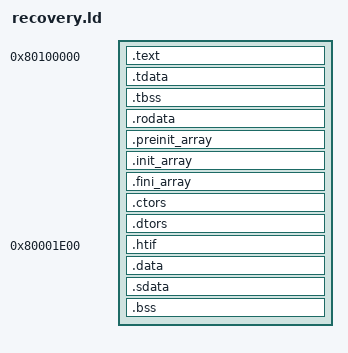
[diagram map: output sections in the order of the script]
/* Linker script for the recovery firmware image.
 * Identical to chipyard's htif.ld except linked at 0x80100000 instead of
 * 0x80000000. The BootROM mret's here when verification fails, emulating
 * production secure-boot recovery firmware loaded into a separate region. */
OUTPUT_ARCH ("riscv")
ENTRY (_start)

SECTIONS
{
    . = 0x80100000;

    /* Keep under a power of 2 to reserve space for TCB */
    PROVIDE (__stack_size_min = 24K);

    .text : {
        *(.text.init)
        *(.text.unlikely .text.unlikely.*)
        *(.text.startup .text.startup.*)
        *(.text .text.*)
        *(.gnu.linkonce.t.*)
    }
    PROVIDE (_etext = .);

    /* Static Thread Local Storage template */
    .tdata : {
        PROVIDE_HIDDEN (__tdata_start = .);
        *(.tdata .tdata.*)
        *(.gnu.linkonce.td.*)
        PROVIDE_HIDDEN (__tdata_end = .);
    }
    PROVIDE (__tdata_size = SIZEOF (.tdata));

    .tbss (NOLOAD) : {
        PROVIDE_HIDDEN (__tbss_start = .);
        PROVIDE_HIDDEN (__tbss_offset = ABSOLUTE (__tbss_start - __tdata_start));
        *(.tbss .tbss.*)
        *(.gnu.linkonce.tb.*)
        *(.tcommon)
        PROVIDE_HIDDEN (__tbss_end = .);
    }
    PROVIDE (__tbss_size = SIZEOF (.tbss));

    .rodata : {
        *(.rodata .rodata.*)
        *(.gnu.linkonce.r.*)
    }

    .preinit_array : {
        PROVIDE_HIDDEN (__preinit_array_start = .);
        KEEP (*(.preinit_array))
        PROVIDE_HIDDEN (__preinit_array_end = .);
    }

    .init_array : {
        PROVIDE_HIDDEN (__init_array_start = .);
        KEEP (*(SORT_BY_INIT_PRIORITY(.init_array.*) SORT_BY_INIT_PRIORITY(.ctors.*)))
        KEEP (*(.init_array EXCLUDE_FILE (*crtbegin.o *crtbegin?.o *crtend.o *crtend?.o ) .ctors))
        PROVIDE_HIDDEN (__init_array_end = .);
    }

    .fini_array : {
        PROVIDE_HIDDEN (__fini_array_start = .);
        KEEP (*(SORT_BY_INIT_PRIORITY(.fini_array.*) SORT_BY_INIT_PRIORITY(.dtors.*)))
        KEEP (*(.fini_array EXCLUDE_FILE (*crtbegin.o *crtbegin?.o *crtend.o *crtend?.o ) .dtors))
        PROVIDE_HIDDEN (__fini_array_end = .);
    }

    .ctors : {
        KEEP (*crtbegin.o(.ctors))
        KEEP (*crtbegin?.o(.ctors))
        KEEP (*(EXCLUDE_FILE (*crtend.o *crtend?.o) .ctors))
        KEEP (*(SORT(.ctors.*)))
        KEEP (*(.ctors))
    }

    .dtors : {
        KEEP (*crtbegin.o(.dtors))
        KEEP (*crtbegin?.o(.dtors))
        KEEP (*(EXCLUDE_FILE (*crtend.o *crtend?.o) .dtors))
        KEEP (*(SORT(.dtors.*)))
        KEEP (*(.dtors))
    }

    /* Host-Target Interface — anchored at 0x80001e00 to match the
     * address FESVR watches (set from kernel.riscv's symbol table, since
     * FESVR's `load_program` reads `tohost_addr` only from `targs[0]`).
     *
     * Why this is needed: htif_nano's `htif_syscall` (used by stdio's
     * `_write`, hence printf) defines `tohost` as `static volatile` in
     * its own translation unit. The reference is PC-relative within the
     * link, so Makefile `--defsym=tohost=...` does NOT redirect it. The
     * only way to redirect htif_syscall's writes to FESVR's watched
     * address is to force the .htif section's VMA there.
     *
     * NOLOAD: recovery doesn't actually place bytes here — kernel.riscv
     * (targs[0]) already loaded initial zero bytes at 0x80001e00 as its
     * own tohost/fromhost slots. Recovery just *references* this region
     * at runtime (via its own htif_syscall) and FESVR is already
     * watching it. */
    save_dot = .;
    .htif 0x80001e00 (NOLOAD) : AT(save_dot) {
        *(.htif)
    }
    . = save_dot;

    .data : ALIGN (8) {
        *(.data)
        *(.gnu.linkonce.d.*)
    }

    .sdata : {
        PROVIDE (__global_pointer$ = . + 0x800);
        *(.sdata .sdata.*)
        *(.gnu.linkonce.s.*)
        *(.srodata.cst16)
        *(.srodata.cst8)
        *(.srodata.cst4)
        *(.srodata.cst2)
        *(.srodata .srodata.*)
    }

    PROVIDE (_edata = .);

    .bss : ALIGN (8) {
        PROVIDE_HIDDEN (__bss_start = .);
        *(.sbss .sbss.*)
        *(.gnu.linkonce.sb.*)
        *(.bss .bss.*)
        *(.gnu.linkonce.b.*)
        *(COMMON)
        PROVIDE_HIDDEN (__bss_end = .);
    }

    . = ALIGN (8);
    PROVIDE (_end = .);

    /* Reserve heap space */
    PROVIDE(__heap_size = 128K);
    . += __heap_size;
    . = ALIGN (4K);
    PROVIDE (__heap_end = .);

    /* Place Thread Control Block (TCB) at bottom of hart stack */
    PROVIDE (__tcb_size = __tbss_end - __tdata_start);
    PROVIDE (__stack_align = MAX (ALIGNOF (.tdata), 0x10));
    PROVIDE (__stack_start = ALIGN (__stack_align));
    PROVIDE (__stack_shift = LOG2CEIL( ALIGN (__stack_size_min + __tcb_size, __stack_align)));
    PROVIDE (__stack_size = 1 << __stack_shift);

    /* Default boot hart */
    PROVIDE (__boot_hart = 0);
}
